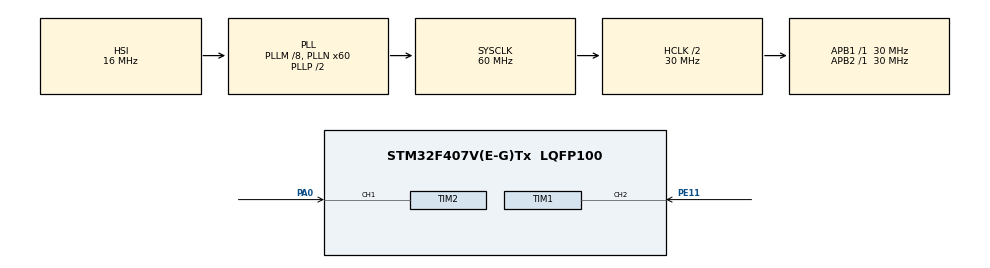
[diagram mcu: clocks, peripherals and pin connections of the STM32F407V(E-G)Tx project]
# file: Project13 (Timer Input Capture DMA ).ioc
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Dma.Request0=TIM1_CH2
Dma.Request1=TIM2_CH1
Dma.TIM1_CH2.0.Direction=DMA_PERIPH_TO_MEMORY
Dma.TIM1_CH2.0.FIFOMode=DMA_FIFOMODE_DISABLE
Dma.TIM1_CH2.0.Instance=DMA2_Stream2
Dma.TIM1_CH2.0.MemDataAlignment=DMA_MDATAALIGN_WORD
Dma.TIM1_CH2.0.MemInc=DMA_MINC_ENABLE
Dma.TIM1_CH2.0.Mode=DMA_CIRCULAR
Dma.TIM1_CH2.0.PeriphDataAlignment=DMA_PDATAALIGN_WORD
Dma.TIM1_CH2.0.PeriphInc=DMA_PINC_DISABLE
Dma.TIM1_CH2.0.Priority=DMA_PRIORITY_LOW
Dma.TIM2_CH1.1.Direction=DMA_PERIPH_TO_MEMORY
Dma.TIM2_CH1.1.FIFOMode=DMA_FIFOMODE_DISABLE
Dma.TIM2_CH1.1.Instance=DMA1_Stream5
Dma.TIM2_CH1.1.MemDataAlignment=DMA_MDATAALIGN_WORD
Dma.TIM2_CH1.1.MemInc=DMA_MINC_ENABLE
Dma.TIM2_CH1.1.Mode=DMA_CIRCULAR
Dma.TIM2_CH1.1.PeriphDataAlignment=DMA_PDATAALIGN_WORD
Dma.TIM2_CH1.1.PeriphInc=DMA_PINC_DISABLE
Dma.TIM2_CH1.1.Priority=DMA_PRIORITY_LOW
Mcu.Family=STM32F4
Mcu.Name=STM32F407V(E-G)Tx
Mcu.Package=LQFP100
NVIC.DMA1_Stream5_IRQn=true\:0\:0\:false\:false\:true\:false\:true\:true
NVIC.DMA2_Stream2_IRQn=true\:0\:0\:false\:false\:true\:false\:true\:true
NVIC.PriorityGroup=NVIC_PRIORITYGROUP_4
PA0-WKUP.Signal=S_TIM2_CH1_ETR
PA13.Mode=Serial_Wire
PA13.Signal=SYS_JTMS-SWDIO
PA14.Mode=Serial_Wire
PA14.Signal=SYS_JTCK-SWCLK
PE11.Signal=S_TIM1_CH2
ProjectManager.HeapSize=0x200
ProjectManager.StackSize=0x400
ProjectManager.TargetToolchain=MDK-ARM V5.32
RCC.48MHZClocksFreq_Value=30000000
RCC.AHBCLKDivider=RCC_SYSCLK_DIV2
RCC.AHBFreq_Value=30000000
RCC.APB1Freq_Value=30000000
RCC.APB1TimFreq_Value=30000000
RCC.APB2Freq_Value=30000000
RCC.APB2TimFreq_Value=30000000
RCC.CortexFreq_Value=30000000
RCC.HCLKFreq_Value=30000000
RCC.HSE_VALUE=25000000
RCC.HSI_VALUE=16000000
RCC.LSE_VALUE=32768
RCC.PLLM=8
RCC.PLLN=60
RCC.SYSCLKFreq_VALUE=60000000
RCC.SYSCLKSource=RCC_SYSCLKSOURCE_PLLCLK
RCC.VCOOutputFreq_Value=120000000
SH.S_TIM1_CH2.0=TIM1_CH2,Input_Capture2_from_TI2
SH.S_TIM2_CH1_ETR.0=TIM2_CH1,Input_Capture1_from_TI1
TIM1.Channel-Input_Capture2_from_TI2=TIM_CHANNEL_2
TIM1.ICFilter_CH2=15
TIM1.Period=65000
TIM1.Prescaler=29999
TIM2.Channel-Input_Capture1_from_TI1=TIM_CHANNEL_1
TIM2.Period=100000
TIM2.Prescaler=29999
VP_TIM1_VS_ClockSourceINT.Mode=Internal
VP_TIM2_VS_ClockSourceINT.Mode=Internal
board=custom

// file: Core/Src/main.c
/* USER CODE BEGIN Header */
/**
  ******************************************************************************
  * @file           : main.c
  * @brief          : Main program body
  ******************************************************************************
  * @attention
  *
  * Copyright (c) 2023 STMicroelectronics.
  * All rights reserved.
  *
  * This software is licensed under terms that can be found in the LICENSE file
  * in the root directory of this software component.
  * If no LICENSE file comes with this software, it is provided AS-IS.
  *
  ******************************************************************************
  */
/* USER CODE END Header */
#include "main.h"

/* USER CODE BEGIN Includes */
uint32_t counter_TIM1=0, counter_TIM2=0;
uint32_t TIM1_DMA[1], TIM2_DMA[1];
/* USER CODE END Includes */

TIM_HandleTypeDef htim1;
TIM_HandleTypeDef htim2;
DMA_HandleTypeDef hdma_tim1_ch2;
DMA_HandleTypeDef hdma_tim2_ch1;

void SystemClock_Config(void);
static void MX_GPIO_Init(void);
static void MX_DMA_Init(void);
static void MX_TIM1_Init(void);
static void MX_TIM2_Init(void);

/* USER CODE BEGIN 0 */
void HAL_TIM_IC_CaptureCallback(TIM_HandleTypeDef *htim){
	if(htim->Instance == TIM1){
		__HAL_TIM_SetCounter(&htim1, 0);
	}
	if(htim->Instance == TIM2){
		__HAL_TIM_SetCounter(&htim2, 0);
	}
}
/* USER CODE END 0 */

int main(void)
{

  /* MCU Configuration--------------------------------------------------------*/

  /* Reset of all peripherals, Initializes the Flash interface and the Systick. */
  HAL_Init();

  /* Configure the system clock */
  SystemClock_Config();

  /* Initialize all configured peripherals */
  MX_GPIO_Init();
  MX_DMA_Init();
  MX_TIM1_Init();
  MX_TIM2_Init();
  /* USER CODE BEGIN 2 */
	HAL_TIM_IC_Start_DMA(&htim1, TIM_CHANNEL_2, (uint32_t*)TIM1_DMA, 1);
	HAL_TIM_IC_Start_DMA(&htim2, TIM_CHANNEL_1, (uint32_t*)TIM2_DMA, 1);
  /* USER CODE END 2 */

  /* Infinite loop */
  while (1)
  {

    /* USER CODE BEGIN 3 */
		HAL_GPIO_ReadPin(GPIOA, GPIO_PIN_0);
		HAL_GPIO_ReadPin(GPIOE, GPIO_PIN_11);
		counter_TIM1 = __HAL_TIM_GetCounter(&htim1);
		counter_TIM2 = __HAL_TIM_GetCounter(&htim2);
  }
  /* USER CODE END 3 */
}

void SystemClock_Config(void)
{
  RCC_OscInitTypeDef RCC_OscInitStruct = {0};
  RCC_ClkInitTypeDef RCC_ClkInitStruct = {0};

  /** Configure the main internal regulator output voltage
  */
  __HAL_RCC_PWR_CLK_ENABLE();
  __HAL_PWR_VOLTAGESCALING_CONFIG(PWR_REGULATOR_VOLTAGE_SCALE1);

  /** Initializes the RCC Oscillators according to the specified parameters
  * in the RCC_OscInitTypeDef structure.
  */
  RCC_OscInitStruct.OscillatorType = RCC_OSCILLATORTYPE_HSI;
  RCC_OscInitStruct.HSIState = RCC_HSI_ON;
  RCC_OscInitStruct.HSICalibrationValue = RCC_HSICALIBRATION_DEFAULT;
  RCC_OscInitStruct.PLL.PLLState = RCC_PLL_ON;
  RCC_OscInitStruct.PLL.PLLSource = RCC_PLLSOURCE_HSI;
  RCC_OscInitStruct.PLL.PLLM = 8;
  RCC_OscInitStruct.PLL.PLLN = 60;
  RCC_OscInitStruct.PLL.PLLP = RCC_PLLP_DIV2;
  RCC_OscInitStruct.PLL.PLLQ = 4;
  if (HAL_RCC_OscConfig(&RCC_OscInitStruct) != HAL_OK)
  {
    Error_Handler();
  }

  /** Initializes the CPU, AHB and APB buses clocks
  */
  RCC_ClkInitStruct.ClockType = RCC_CLOCKTYPE_HCLK|RCC_CLOCKTYPE_SYSCLK
                              |RCC_CLOCKTYPE_PCLK1|RCC_CLOCKTYPE_PCLK2;
  RCC_ClkInitStruct.SYSCLKSource = RCC_SYSCLKSOURCE_PLLCLK;
  RCC_ClkInitStruct.AHBCLKDivider = RCC_SYSCLK_DIV2;
  RCC_ClkInitStruct.APB1CLKDivider = RCC_HCLK_DIV1;
  RCC_ClkInitStruct.APB2CLKDivider = RCC_HCLK_DIV1;

  if (HAL_RCC_ClockConfig(&RCC_ClkInitStruct, FLASH_LATENCY_0) != HAL_OK)
  {
    Error_Handler();
  }
}

static void MX_TIM1_Init(void)
{

  TIM_ClockConfigTypeDef sClockSourceConfig = {0};
  TIM_MasterConfigTypeDef sMasterConfig = {0};
  TIM_IC_InitTypeDef sConfigIC = {0};

  htim1.Instance = TIM1;
  htim1.Init.Prescaler = 29999;
  htim1.Init.CounterMode = TIM_COUNTERMODE_UP;
  htim1.Init.Period = 65000;
  htim1.Init.ClockDivision = TIM_CLOCKDIVISION_DIV1;
  htim1.Init.RepetitionCounter = 0;
  htim1.Init.AutoReloadPreload = TIM_AUTORELOAD_PRELOAD_DISABLE;
  if (HAL_TIM_Base_Init(&htim1) != HAL_OK)
  {
    Error_Handler();
  }
  sClockSourceConfig.ClockSource = TIM_CLOCKSOURCE_INTERNAL;
  if (HAL_TIM_ConfigClockSource(&htim1, &sClockSourceConfig) != HAL_OK)
  {
    Error_Handler();
  }
  if (HAL_TIM_IC_Init(&htim1) != HAL_OK)
  {
    Error_Handler();
  }
  sMasterConfig.MasterOutputTrigger = TIM_TRGO_RESET;
  sMasterConfig.MasterSlaveMode = TIM_MASTERSLAVEMODE_DISABLE;
  if (HAL_TIMEx_MasterConfigSynchronization(&htim1, &sMasterConfig) != HAL_OK)
  {
    Error_Handler();
  }
  sConfigIC.ICPolarity = TIM_INPUTCHANNELPOLARITY_RISING;
  sConfigIC.ICSelection = TIM_ICSELECTION_DIRECTTI;
  sConfigIC.ICPrescaler = TIM_ICPSC_DIV1;
  sConfigIC.ICFilter = 15;
  if (HAL_TIM_IC_ConfigChannel(&htim1, &sConfigIC, TIM_CHANNEL_2) != HAL_OK)
  {
    Error_Handler();
  }

}

static void MX_TIM2_Init(void)
{

  TIM_ClockConfigTypeDef sClockSourceConfig = {0};
  TIM_MasterConfigTypeDef sMasterConfig = {0};
  TIM_IC_InitTypeDef sConfigIC = {0};

  htim2.Instance = TIM2;
  htim2.Init.Prescaler = 29999;
  htim2.Init.CounterMode = TIM_COUNTERMODE_UP;
  htim2.Init.Period = 100000;
  htim2.Init.ClockDivision = TIM_CLOCKDIVISION_DIV1;
  htim2.Init.AutoReloadPreload = TIM_AUTORELOAD_PRELOAD_DISABLE;
  if (HAL_TIM_Base_Init(&htim2) != HAL_OK)
  {
    Error_Handler();
  }
  sClockSourceConfig.ClockSource = TIM_CLOCKSOURCE_INTERNAL;
  if (HAL_TIM_ConfigClockSource(&htim2, &sClockSourceConfig) != HAL_OK)
  {
    Error_Handler();
  }
  if (HAL_TIM_IC_Init(&htim2) != HAL_OK)
  {
    Error_Handler();
  }
  sMasterConfig.MasterOutputTrigger = TIM_TRGO_RESET;
  sMasterConfig.MasterSlaveMode = TIM_MASTERSLAVEMODE_DISABLE;
  if (HAL_TIMEx_MasterConfigSynchronization(&htim2, &sMasterConfig) != HAL_OK)
  {
    Error_Handler();
  }
  sConfigIC.ICPolarity = TIM_INPUTCHANNELPOLARITY_RISING;
  sConfigIC.ICSelection = TIM_ICSELECTION_DIRECTTI;
  sConfigIC.ICPrescaler = TIM_ICPSC_DIV1;
  sConfigIC.ICFilter = 0;
  if (HAL_TIM_IC_ConfigChannel(&htim2, &sConfigIC, TIM_CHANNEL_1) != HAL_OK)
  {
    Error_Handler();
  }

}

static void MX_DMA_Init(void)
{

  /* DMA controller clock enable */
  __HAL_RCC_DMA2_CLK_ENABLE();
  __HAL_RCC_DMA1_CLK_ENABLE();

  /* DMA interrupt init */
  /* DMA1_Stream5_IRQn interrupt configuration */
  HAL_NVIC_SetPriority(DMA1_Stream5_IRQn, 0, 0);
  HAL_NVIC_EnableIRQ(DMA1_Stream5_IRQn);
  /* DMA2_Stream2_IRQn interrupt configuration */
  HAL_NVIC_SetPriority(DMA2_Stream2_IRQn, 0, 0);
  HAL_NVIC_EnableIRQ(DMA2_Stream2_IRQn);

}

static void MX_GPIO_Init(void)
{

  /* GPIO Ports Clock Enable */
  __HAL_RCC_GPIOA_CLK_ENABLE();
  __HAL_RCC_GPIOE_CLK_ENABLE();

}

void Error_Handler(void)
{
  __disable_irq();
  while (1)
  {
  }
}
